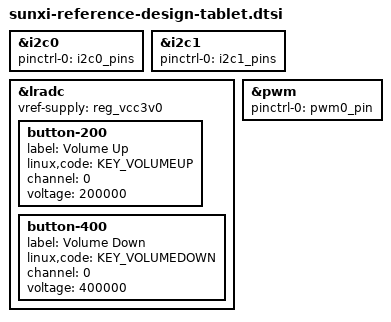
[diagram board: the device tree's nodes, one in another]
#include <dt-bindings/gpio/gpio.h>
#include <dt-bindings/input/input.h>
#include "sunxi-common-regulators.dtsi"
&i2c0 {
	pinctrl-names = "default";
	pinctrl-0 = <&i2c0_pins>;
	status = "okay";
};
&i2c1 {
	pinctrl-names = "default";
	pinctrl-0 = <&i2c1_pins>;
	status = "okay";
};
&lradc {
	vref-supply = <&reg_vcc3v0>;
	status = "okay";
	button-200 {
		label = "Volume Up";
		linux,code = <KEY_VOLUMEUP>;
		channel = <0>;
		voltage = <200000>;
	};
	button-400 {
		label = "Volume Down";
		linux,code = <KEY_VOLUMEDOWN>;
		channel = <0>;
		voltage = <400000>;
	};
};
&pwm {
	pinctrl-names = "default";
	pinctrl-0 = <&pwm0_pin>;
	status = "okay";
};
